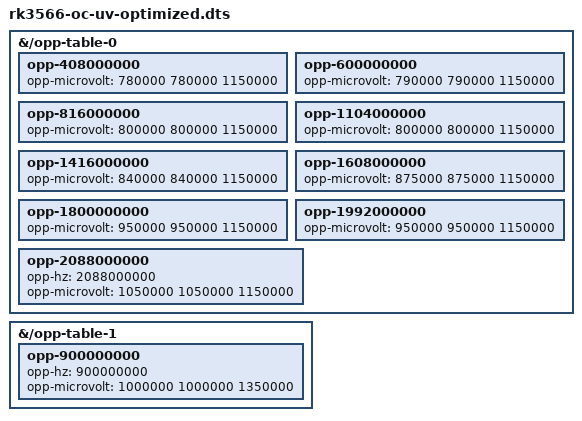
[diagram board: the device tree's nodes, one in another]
/*
 * RK3566 Optimized Overclock + Undervolt
 *
 * Combined OC+UV curve from 29-run profiling campaign + 7.0-rc4
 * regression analysis (R19-R20, alpha=0.76, R² > 0.98).
 *
 * CPU: Boost OPPs at validated voltages.
 *   1800 MHz @ 950 mV — revised from 900mV (12.5% 1T loss → ~8%)
 *   1992 MHz @ 950 mV — proven stable (UV-optimal)
 *   2088 MHz @ 1050 mV — ATF-validated, within stock envelope
 *
 * GPU: 900 MHz OPP (Mali-G52 EE, validated on RK3562 same IP).
 *
 * Overall: 28% power reduction vs stock, 4T stable all governors.
 */
/dts-v1/;
/plugin/;

/ {
fragment@0 {
	target-path = "/opp-table-0";
	__overlay__ {
		opp-408000000  { opp-microvolt = <780000 780000 1150000>; };
		opp-600000000  { opp-microvolt = <790000 790000 1150000>; };
		opp-816000000  { opp-microvolt = <800000 800000 1150000>; };
		opp-1104000000 { opp-microvolt = <800000 800000 1150000>; };
		opp-1416000000 { opp-microvolt = <840000 840000 1150000>; };
		opp-1608000000 { opp-microvolt = <875000 875000 1150000>; };
		opp-1800000000 { opp-microvolt = <950000 950000 1150000>; };
		opp-1992000000 { opp-microvolt = <950000 950000 1150000>; };
		opp-2088000000 {
			opp-hz = /bits/ 64 <2088000000>;
			opp-microvolt = <1050000 1050000 1150000>;
		};
	};
};
fragment@1 {
	target-path = "/opp-table-1";
	__overlay__ {
		opp-900000000 {
			opp-hz = /bits/ 64 <900000000>;
			opp-microvolt = <1000000 1000000 1350000>;
		};
	};
};
};
